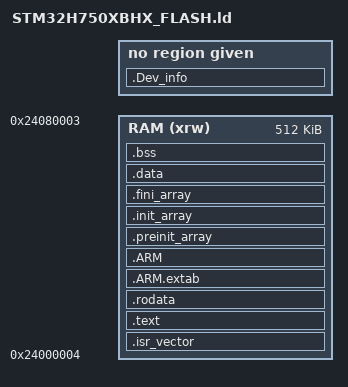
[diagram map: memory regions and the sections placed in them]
/*
******************************************************************************
**

**  File        : LinkerScript.ld
**
**
**  Abstract    : Linker script for STM32H7 series
**                1024Kbytes FLASH and 192Kbytes RAM
**
**                Set heap size, stack size and stack location according
**                to application requirements.
**
**                Set memory bank area and size if external memory is used.
**
**  Target      : STMicroelectronics STM32
**
**  Distribution: The file is distributed as is, without any warranty
**                of any kind.
**
*****************************************************************************
** @attention
**
** Copyright (c) 2019 STMicroelectronics.
** All rights reserved.
**
** This software component is licensed by ST under BSD 3-Clause license,
** the "License"; You may not use this file except in compliance with the
** License. You may obtain a copy of the License at:
**                        opensource.org/licenses/BSD-3-Clause
**
****************************************************************************
*/

/* Entry Point */
ENTRY(Init)

/* Generate 2 segment for loader code and device info */
PHDRS {Loader PT_LOAD; SgInfo PT_LOAD ; }

/* Specify the memory areas */
MEMORY
{
  RAM (xrw)       : ORIGIN = 0x24000004, LENGTH = 512K
}

/* Define output sections */
SECTIONS
{
  
  
  .isr_vector :
  {
    __isr_vector_addr = .;
    __isr_vector = .;
      
    . = ALIGN(4);
    KEEP(*(.isr_vector)) /* Startup code */
    . = ALIGN(4);
  } >RAM :Loader
  
  
  /* The program code and other data goes into FLASH */
  .text :
  {
    . = ALIGN(4);
    *(.text)           /* .text sections (code) */
    *(.text*)          /* .text* sections (code) */

    KEEP (*(.init))
    KEEP (*(.fini))

    . = ALIGN(4);
    _etext = .;        /* define a global symbols at end of code */
  } >RAM :Loader

    .Dev_info :
  {
	KEEP(*(.Dev_info ))
  } :SgInfo
  
  /* Constant data goes into FLASH */
  .rodata :
  {
    . = ALIGN(4);
    *(.rodata)         /* .rodata sections (constants, strings, etc.) */
    *(.rodata*)        /* .rodata* sections (constants, strings, etc.) */
    . = ALIGN(4);
  } >RAM :Loader

  .ARM.extab   : { *(.ARM.extab* .gnu.linkonce.armextab.*) } >RAM
  .ARM : {
    __exidx_start = .;
    *(.ARM.exidx*)
    __exidx_end = .;
  } >RAM :Loader

  .preinit_array     :
  {
    PROVIDE_HIDDEN (__preinit_array_start = .);
    KEEP (*(.preinit_array*))
    PROVIDE_HIDDEN (__preinit_array_end = .);
  } >RAM :Loader
  
  .init_array :
  {
    PROVIDE_HIDDEN (__init_array_start = .);
    KEEP (*(SORT(.init_array.*)))
    KEEP (*(.init_array*))
    PROVIDE_HIDDEN (__init_array_end = .);
  } >RAM :Loader
  
  .fini_array :
  {
    PROVIDE_HIDDEN (__fini_array_start = .);
    KEEP (*(SORT(.fini_array.*)))
    KEEP (*(.fini_array*))
    PROVIDE_HIDDEN (__fini_array_end = .);
  } >RAM :Loader

  /* used by the startup to initialize data */
  _sidata = LOADADDR(.data);

  /* Initialized data sections goes into RAM, load LMA copy after code */
  .data : 
  {
    . = ALIGN(4);
    _sdata = .;        /* create a global symbol at data start */
    *(.data)           /* .data sections */
    *(.data*)          /* .data* sections */

    . = ALIGN(4);
    _edata = .;        /* define a global symbol at data end */
  } >RAM :Loader

  /* Uninitialized data section */
  . = ALIGN(4);
  .bss :
  {
    /* This is used by the startup in order to initialize the .bss secion */
    _sbss = .;         /* define a global symbol at bss start */
    __bss_start__ = _sbss;
    *(.bss)
    *(.bss*)
    *(COMMON)

    . = ALIGN(4);
    _ebss = .;         /* define a global symbol at bss end */
    __bss_end__ = _ebss;
  } >RAM :Loader

  /* Remove information from the standard libraries */
  /DISCARD/ :
  {
    libc.a ( * )
    libm.a ( * )
    libgcc.a ( * )
  }

  .ARM.attributes 0 : { *(.ARM.attributes) }
}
